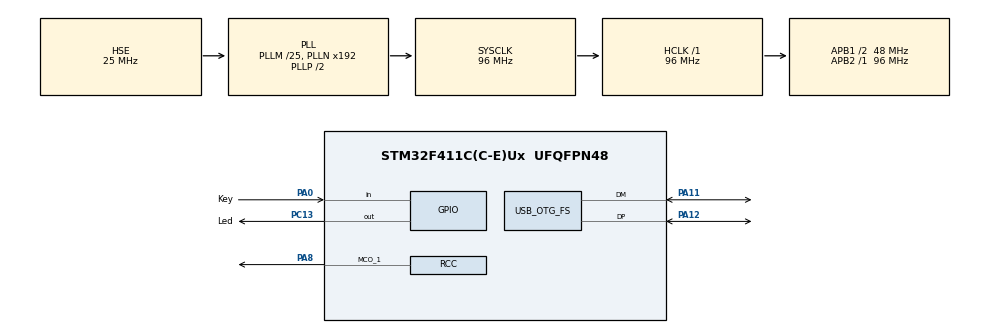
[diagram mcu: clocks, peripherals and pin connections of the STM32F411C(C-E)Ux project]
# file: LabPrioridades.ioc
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FREERTOS.Tasks01=defaultTask,0,128,StartDefaultTask,Default,NULL,Dynamic,NULL,NULL;Task02,0,128,Tarefa2,Default,NULL,Dynamic,NULL,NULL;Task03,0,128,Tarefa3,Default,NULL,Dynamic,NULL,NULL
FREERTOS.configTICK_RATE_HZ=100
Mcu.Family=STM32F4
Mcu.Name=STM32F411C(C-E)Ux
Mcu.Package=UFQFPN48
NVIC.OTG_FS_IRQn=true\:5\:0\:false\:false\:true\:true\:false\:true
NVIC.PriorityGroup=NVIC_PRIORITYGROUP_4
NVIC.TIM1_TRG_COM_TIM11_IRQn=true\:0\:0\:false\:false\:true\:false\:false\:true
NVIC.TimeBase=TIM1_TRG_COM_TIM11_IRQn
NVIC.TimeBaseIP=TIM11
PA0-WKUP.GPIO_Label=Key
PA0-WKUP.GPIO_PuPd=GPIO_PULLUP
PA0-WKUP.Signal=GPIO_Input
PA11.Mode=Device_Only
PA11.Signal=USB_OTG_FS_DM
PA12.Mode=Device_Only
PA12.Signal=USB_OTG_FS_DP
PA13.Mode=Serial_Wire
PA13.Signal=SYS_JTMS-SWDIO
PA14.Mode=Serial_Wire
PA14.Signal=SYS_JTCK-SWCLK
PA8.Mode=Clock-out-1
PA8.Signal=RCC_MCO_1
PC13-ANTI_TAMP.GPIO_Label=Led
PC13-ANTI_TAMP.PinState=GPIO_PIN_SET
PC13-ANTI_TAMP.Signal=GPIO_Output
PC14-OSC32_IN.Mode=LSE-External-Oscillator
PC14-OSC32_IN.Signal=RCC_OSC32_IN
PC15-OSC32_OUT.Mode=LSE-External-Oscillator
PC15-OSC32_OUT.Signal=RCC_OSC32_OUT
PH0\ -\ OSC_IN.Mode=HSE-External-Oscillator
PH0\ -\ OSC_IN.Signal=RCC_OSC_IN
PH1\ -\ OSC_OUT.Mode=HSE-External-Oscillator
PH1\ -\ OSC_OUT.Signal=RCC_OSC_OUT
ProjectManager.HeapSize=0x800
ProjectManager.StackSize=0x400
ProjectManager.TargetToolchain=MDK-ARM V5.27
RCC.48MHZClocksFreq_Value=48000000
RCC.AHBFreq_Value=96000000
RCC.APB1CLKDivider=RCC_HCLK_DIV2
RCC.APB1Freq_Value=48000000
RCC.APB1TimFreq_Value=96000000
RCC.APB2Freq_Value=96000000
RCC.APB2TimFreq_Value=96000000
RCC.CortexFreq_Value=96000000
RCC.HCLKFreq_Value=96000000
RCC.HSE_VALUE=25000000
RCC.HSI_VALUE=16000000
RCC.PLLM=25
RCC.SYSCLKFreq_VALUE=96000000
RCC.SYSCLKSource=RCC_SYSCLKSOURCE_PLLCLK
RCC.VCOOutputFreq_Value=192000000
USB_DEVICE.CLASS_NAME_FS=CDC
USB_DEVICE.VirtualMode=Cdc
USB_DEVICE.VirtualModeFS=Cdc_FS
USB_OTG_FS.VirtualMode=Device_Only
VP_FREERTOS_VS_CMSIS_V1.Mode=CMSIS_V1
VP_SYS_VS_tim11.Mode=TIM11
VP_USB_DEVICE_VS_USB_DEVICE_CDC_FS.Mode=CDC_FS
board=custom

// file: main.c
/* USER CODE BEGIN Header */
/**
  ******************************************************************************
  * @file           : main.c
  * @brief          : Main program body
  ******************************************************************************
  * @attention
  *
  * <h2><center>&copy; Copyright (c) 2021 STMicroelectronics.
  * All rights reserved.</center></h2>
  *
  * This software component is licensed by ST under Ultimate Liberty license
  * SLA0044, the "License"; You may not use this file except in compliance with
  * the License. You may obtain a copy of the License at:
  *                             www.st.com/SLA0044
  *
  ******************************************************************************
  */
/* USER CODE END Header */
#include "main.h"
#include "cmsis_os.h"
#include "usb_device.h"

/* USER CODE BEGIN Includes */
#include "usbd_cdc_if.h"
/* USER CODE END Includes */

osThreadId defaultTaskHandle;
osThreadId Task02Handle;
osThreadId Task03Handle;

void SystemClock_Config(void);
static void MX_GPIO_Init(void);
void StartDefaultTask(void const * argument);
void Tarefa2(void const * argument);
void Tarefa3(void const * argument);

int main(void)
{

  /* MCU Configuration--------------------------------------------------------*/

  /* Reset of all peripherals, Initializes the Flash interface and the Systick. */
  HAL_Init();

  /* Configure the system clock */
  SystemClock_Config();

  /* Initialize all configured peripherals */
  MX_GPIO_Init();

  /* Create the thread(s) */
  /* definition and creation of defaultTask */
  osThreadDef(defaultTask, StartDefaultTask, osPriorityNormal, 0, 128);
  defaultTaskHandle = osThreadCreate(osThread(defaultTask), NULL);

  /* definition and creation of Task02 */
  osThreadDef(Task02, Tarefa2, osPriorityNormal, 0, 128);
  Task02Handle = osThreadCreate(osThread(Task02), NULL);

  /* definition and creation of Task03 */
  osThreadDef(Task03, Tarefa3, osPriorityAboveNormal, 0, 128);
  Task03Handle = osThreadCreate(osThread(Task03), NULL);

  /* Start scheduler */
  osKernelStart();

  /* We should never get here as control is now taken by the scheduler */
  /* Infinite loop */
  while (1)
  {

  }
}

void SystemClock_Config(void)
{
  RCC_OscInitTypeDef RCC_OscInitStruct = {0};
  RCC_ClkInitTypeDef RCC_ClkInitStruct = {0};

  /** Configure the main internal regulator output voltage
  */
  __HAL_RCC_PWR_CLK_ENABLE();
  __HAL_PWR_VOLTAGESCALING_CONFIG(PWR_REGULATOR_VOLTAGE_SCALE1);
  /** Initializes the RCC Oscillators according to the specified parameters
  * in the RCC_OscInitTypeDef structure.
  */
  RCC_OscInitStruct.OscillatorType = RCC_OSCILLATORTYPE_HSI|RCC_OSCILLATORTYPE_HSE;
  RCC_OscInitStruct.HSEState = RCC_HSE_ON;
  RCC_OscInitStruct.HSIState = RCC_HSI_ON;
  RCC_OscInitStruct.HSICalibrationValue = RCC_HSICALIBRATION_DEFAULT;
  RCC_OscInitStruct.PLL.PLLState = RCC_PLL_ON;
  RCC_OscInitStruct.PLL.PLLSource = RCC_PLLSOURCE_HSE;
  RCC_OscInitStruct.PLL.PLLM = 25;
  RCC_OscInitStruct.PLL.PLLN = 192;
  RCC_OscInitStruct.PLL.PLLP = RCC_PLLP_DIV2;
  RCC_OscInitStruct.PLL.PLLQ = 4;
  if (HAL_RCC_OscConfig(&RCC_OscInitStruct) != HAL_OK)
  {
    Error_Handler();
  }
  /** Initializes the CPU, AHB and APB buses clocks
  */
  RCC_ClkInitStruct.ClockType = RCC_CLOCKTYPE_HCLK|RCC_CLOCKTYPE_SYSCLK
                              |RCC_CLOCKTYPE_PCLK1|RCC_CLOCKTYPE_PCLK2;
  RCC_ClkInitStruct.SYSCLKSource = RCC_SYSCLKSOURCE_PLLCLK;
  RCC_ClkInitStruct.AHBCLKDivider = RCC_SYSCLK_DIV1;
  RCC_ClkInitStruct.APB1CLKDivider = RCC_HCLK_DIV2;
  RCC_ClkInitStruct.APB2CLKDivider = RCC_HCLK_DIV1;

  if (HAL_RCC_ClockConfig(&RCC_ClkInitStruct, FLASH_LATENCY_3) != HAL_OK)
  {
    Error_Handler();
  }
  HAL_RCC_MCOConfig(RCC_MCO1, RCC_MCO1SOURCE_HSI, RCC_MCODIV_1);
}

static void MX_GPIO_Init(void)
{
  GPIO_InitTypeDef GPIO_InitStruct = {0};

  /* GPIO Ports Clock Enable */
  __HAL_RCC_GPIOC_CLK_ENABLE();
  __HAL_RCC_GPIOH_CLK_ENABLE();
  __HAL_RCC_GPIOA_CLK_ENABLE();

  /*Configure GPIO pin Output Level */
  HAL_GPIO_WritePin(Led_GPIO_Port, Led_Pin, GPIO_PIN_SET);

  /*Configure GPIO pin : Led_Pin */
  GPIO_InitStruct.Pin = Led_Pin;
  GPIO_InitStruct.Mode = GPIO_MODE_OUTPUT_PP;
  GPIO_InitStruct.Pull = GPIO_NOPULL;
  GPIO_InitStruct.Speed = GPIO_SPEED_FREQ_LOW;
  HAL_GPIO_Init(Led_GPIO_Port, &GPIO_InitStruct);

  /*Configure GPIO pin : Key_Pin */
  GPIO_InitStruct.Pin = Key_Pin;
  GPIO_InitStruct.Mode = GPIO_MODE_INPUT;
  GPIO_InitStruct.Pull = GPIO_PULLUP;
  HAL_GPIO_Init(Key_GPIO_Port, &GPIO_InitStruct);

  /*Configure GPIO pin : PA8 */
  GPIO_InitStruct.Pin = GPIO_PIN_8;
  GPIO_InitStruct.Mode = GPIO_MODE_AF_PP;
  GPIO_InitStruct.Pull = GPIO_NOPULL;
  GPIO_InitStruct.Speed = GPIO_SPEED_FREQ_LOW;
  GPIO_InitStruct.Alternate = GPIO_AF0_MCO;
  HAL_GPIO_Init(GPIOA, &GPIO_InitStruct);

}

void StartDefaultTask(void const * argument)
{
  /* init code for USB_DEVICE */
  MX_USB_DEVICE_Init();
  /* USER CODE BEGIN 5 */
  /* Infinite loop */
  for(;;)
  {
		HAL_GPIO_TogglePin(Led_GPIO_Port, Led_Pin);
    osDelay(250);
  }
  /* USER CODE END 5 */
}

void Tarefa2(void const * argument)
{
  /* USER CODE BEGIN Tarefa2 */
	uint8_t string2[10]="Task2 OK!\n";
	uint32_t count;
  /* Infinite loop */
  for(;;)
  {
		CDC_Transmit_FS(string2, sizeof(string2)-1);
    for(count = 0; count < 0x07FFFFF; count++){}
  }
  /* USER CODE END Tarefa2 */
}

void Tarefa3(void const * argument)
{
  /* USER CODE BEGIN Tarefa3 */
	uint8_t string3[10]="Task3 OK!\n";
  /* Infinite loop */
  for(;;)
  {
    CDC_Transmit_FS(string3, sizeof(string3)-1);
		osDelay(1000);
  }
  /* USER CODE END Tarefa3 */
}

void HAL_TIM_PeriodElapsedCallback(TIM_HandleTypeDef *htim)
{
  if (htim->Instance == TIM11) {
    HAL_IncTick();
  }
}

void Error_Handler(void)
{
}

/************************ (C) COPYRIGHT STMicroelectronics *****END OF FILE****/
